AUTOSAR XML (schema 00049)
package /Components
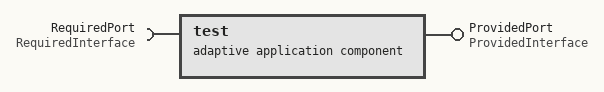
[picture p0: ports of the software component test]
  adaptive application sw component type test
    require port RequiredPort: queued-receiver-com-spec=data-element=In1, required-interface=RequiredInterface
    provide port ProvidedPort: queued-sender-com-spec=data-element=Out1, provided-interface=ProvidedInterface
